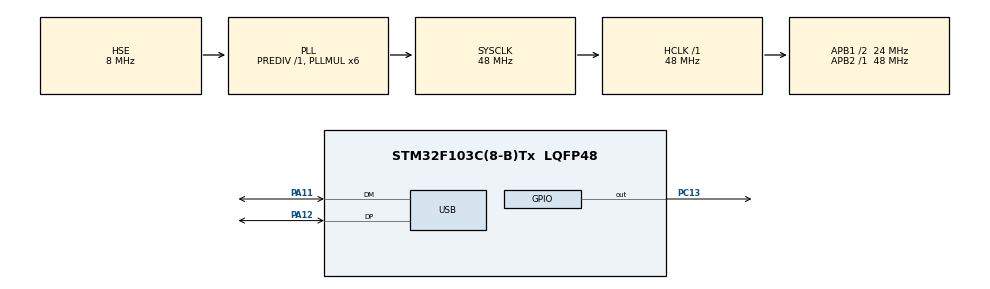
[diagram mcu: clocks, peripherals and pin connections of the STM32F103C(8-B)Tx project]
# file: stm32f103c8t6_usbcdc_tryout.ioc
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Mcu.Family=STM32F1
Mcu.Name=STM32F103C(8-B)Tx
Mcu.Package=LQFP48
NVIC.PriorityGroup=NVIC_PRIORITYGROUP_4
NVIC.USB_LP_CAN1_RX0_IRQn=true\:0\:0\:false\:false\:true\:false
PA11.Mode=Device
PA11.Signal=USB_DM
PA12.Mode=Device
PA12.Signal=USB_DP
PA13.Mode=Serial_Wire
PA13.Signal=SYS_JTMS-SWDIO
PA14.Mode=Serial_Wire
PA14.Signal=SYS_JTCK-SWCLK
PC13-TAMPER-RTC.PinState=GPIO_PIN_RESET
PC13-TAMPER-RTC.Signal=GPIO_Output
PD0-OSC_IN.Mode=HSE-External-Oscillator
PD0-OSC_IN.Signal=RCC_OSC_IN
PD1-OSC_OUT.Mode=HSE-External-Oscillator
PD1-OSC_OUT.Signal=RCC_OSC_OUT
ProjectManager.HeapSize=0x200
ProjectManager.StackSize=0x400
ProjectManager.TargetToolchain=Makefile
RCC.AHBFreq_Value=48000000
RCC.APB1CLKDivider=RCC_HCLK_DIV2
RCC.APB1Freq_Value=24000000
RCC.APB1TimFreq_Value=48000000
RCC.APB2Freq_Value=48000000
RCC.APB2TimFreq_Value=48000000
RCC.HCLKFreq_Value=48000000
RCC.PLLMUL=RCC_PLL_MUL6
RCC.PLLSourceVirtual=RCC_PLLSOURCE_HSE
RCC.SYSCLKFreq_VALUE=48000000
RCC.SYSCLKSource=RCC_SYSCLKSOURCE_PLLCLK
RCC.USBFreq_Value=48000000
USB_DEVICE.CLASS_NAME_FS=CDC
USB_DEVICE.USBD_MAX_NUM_INTERFACES=1
USB_DEVICE.VirtualMode=Cdc
USB_DEVICE.VirtualModeFS=Cdc_FS
VP_USB_DEVICE_VS_USB_DEVICE_CDC_FS.Mode=CDC_FS
board=custom

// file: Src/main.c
/* USER CODE BEGIN Header */
/**
  ******************************************************************************
  * @file           : main.c
  * @brief          : Main program body
  ******************************************************************************
  * This notice applies to any and all portions of this file
  * that are not between comment pairs USER CODE BEGIN and
  * USER CODE END. Other portions of this file, whether
  * inserted by the user or by software development tools
  * are owned by their respective copyright owners.
  *
  * Copyright (c) 2019 STMicroelectronics International N.V.
  * All rights reserved.
  *
  * Redistribution and use in source and binary forms, with or without
  * modification, are permitted, provided that the following conditions are met:
  *
  * 1. Redistribution of source code must retain the above copyright notice,
  *    this list of conditions and the following disclaimer.
  * 2. Redistributions in binary form must reproduce the above copyright notice,
  *    this list of conditions and the following disclaimer in the documentation
  *    and/or other materials provided with the distribution.
  * 3. Neither the name of STMicroelectronics nor the names of other
  *    contributors to this software may be used to endorse or promote products
  *    derived from this software without specific written permission.
  * 4. This software, including modifications and/or derivative works of this
  *    software, must execute solely and exclusively on microcontroller or
  *    microprocessor devices manufactured by or for STMicroelectronics.
  * 5. Redistribution and use of this software other than as permitted under
  *    this license is void and will automatically terminate your rights under
  *    this license.
  *
  * THIS SOFTWARE IS PROVIDED BY STMICROELECTRONICS AND CONTRIBUTORS "AS IS"
  * AND ANY EXPRESS, IMPLIED OR STATUTORY WARRANTIES, INCLUDING, BUT NOT
  * LIMITED TO, THE IMPLIED WARRANTIES OF MERCHANTABILITY, FITNESS FOR A
  * PARTICULAR PURPOSE AND NON-INFRINGEMENT OF THIRD PARTY INTELLECTUAL PROPERTY
  * RIGHTS ARE DISCLAIMED TO THE FULLEST EXTENT PERMITTED BY LAW. IN NO EVENT
  * SHALL STMICROELECTRONICS OR CONTRIBUTORS BE LIABLE FOR ANY DIRECT, INDIRECT,
  * INCIDENTAL, SPECIAL, EXEMPLARY, OR CONSEQUENTIAL DAMAGES (INCLUDING, BUT NOT
  * LIMITED TO, PROCUREMENT OF SUBSTITUTE GOODS OR SERVICES; LOSS OF USE, DATA,
  * OR PROFITS; OR BUSINESS INTERRUPTION) HOWEVER CAUSED AND ON ANY THEORY OF
  * LIABILITY, WHETHER IN CONTRACT, STRICT LIABILITY, OR TORT (INCLUDING
  * NEGLIGENCE OR OTHERWISE) ARISING IN ANY WAY OUT OF THE USE OF THIS SOFTWARE,
  * EVEN IF ADVISED OF THE POSSIBILITY OF SUCH DAMAGE.
  *
  ******************************************************************************
  */
/* USER CODE END Header */

#include "main.h"
#include "usb_device.h"
#include "gpio.h"

/* USER CODE BEGIN PV */
#define AT_COMMAND_STACK_MAX 100
uint8_t MAX_NUM_AT_COMMAND_STACK = AT_COMMAND_STACK_MAX;
char AT_COMMAND_STACK[AT_COMMAND_STACK_MAX];

uint8_t data_process = 0;

extern uint8_t rece_buf_count;
char temp_rece_data[AT_COMMAND_STACK_MAX];

/* USER CODE END PV */

void SystemClock_Config(void);
/* USER CODE BEGIN PFP */

uint8_t try_send_until_done(uint8_t s_temp[]);

/* USER CODE END PFP */

/* USER CODE BEGIN 0 */

uint8_t try_send_until_done(uint8_t s_temp[])
{
  uint8_t ret_code=-1;
  ret_code=CDC_Transmit_FS(s_temp, strlen(s_temp));

  return ret_code;
}

/* USER CODE END 0 */

int main(void)
{

  /* MCU Configuration--------------------------------------------------------*/

  /* Reset of all peripherals, Initializes the Flash interface and the Systick. */
  HAL_Init();

  /* Configure the system clock */
  SystemClock_Config();

  /* Initialize all configured peripherals */
  MX_GPIO_Init();
  MX_USB_DEVICE_Init();
  /* USER CODE BEGIN 2 */

  data_process=0;

  /* USER CODE END 2 */

  /* Infinite loop */
  while (1)
  {

    /* USER CODE BEGIN 3 */

    if (data_process)
    {
      CDC_Transmit_FS((uint8_t *)temp_rece_data, strlen(temp_rece_data));

      clean_usb_rx_buffer();
      data_process=0;
      rece_buf_count=0;
    }else{
      HAL_Delay(100);
    }

  }

  /* USER CODE END 3 */
}

void SystemClock_Config(void)
{
  RCC_OscInitTypeDef RCC_OscInitStruct = {0};
  RCC_ClkInitTypeDef RCC_ClkInitStruct = {0};
  RCC_PeriphCLKInitTypeDef PeriphClkInit = {0};

  /**Initializes the CPU, AHB and APB busses clocks
  */
  RCC_OscInitStruct.OscillatorType = RCC_OSCILLATORTYPE_HSE;
  RCC_OscInitStruct.HSEState = RCC_HSE_ON;
  RCC_OscInitStruct.HSEPredivValue = RCC_HSE_PREDIV_DIV1;
  RCC_OscInitStruct.HSIState = RCC_HSI_ON;
  RCC_OscInitStruct.PLL.PLLState = RCC_PLL_ON;
  RCC_OscInitStruct.PLL.PLLSource = RCC_PLLSOURCE_HSE;
  RCC_OscInitStruct.PLL.PLLMUL = RCC_PLL_MUL6;
  if (HAL_RCC_OscConfig(&RCC_OscInitStruct) != HAL_OK)
  {
    Error_Handler();
  }
  /**Initializes the CPU, AHB and APB busses clocks
  */
  RCC_ClkInitStruct.ClockType = RCC_CLOCKTYPE_HCLK|RCC_CLOCKTYPE_SYSCLK
                              |RCC_CLOCKTYPE_PCLK1|RCC_CLOCKTYPE_PCLK2;
  RCC_ClkInitStruct.SYSCLKSource = RCC_SYSCLKSOURCE_PLLCLK;
  RCC_ClkInitStruct.AHBCLKDivider = RCC_SYSCLK_DIV1;
  RCC_ClkInitStruct.APB1CLKDivider = RCC_HCLK_DIV2;
  RCC_ClkInitStruct.APB2CLKDivider = RCC_HCLK_DIV1;

  if (HAL_RCC_ClockConfig(&RCC_ClkInitStruct, FLASH_LATENCY_1) != HAL_OK)
  {
    Error_Handler();
  }
  PeriphClkInit.PeriphClockSelection = RCC_PERIPHCLK_USB;
  PeriphClkInit.UsbClockSelection = RCC_USBCLKSOURCE_PLL;
  if (HAL_RCCEx_PeriphCLKConfig(&PeriphClkInit) != HAL_OK)
  {
    Error_Handler();
  }
}

void Error_Handler(void)
{
}

/************************ (C) COPYRIGHT STMicroelectronics *****END OF FILE****/
